# Q32M210 register map
File version: 1.0
Registers are 32-bit, read-write, no defined reset value unless marked. A register's access mark holds for its fields unless they carry their own. Offsets are from the block's base; [hi:lo] are bit positions; {n}, {i} and the like mark numbered series.

## DMA_Controller_Configuration_and_Control
Base 0x40000200
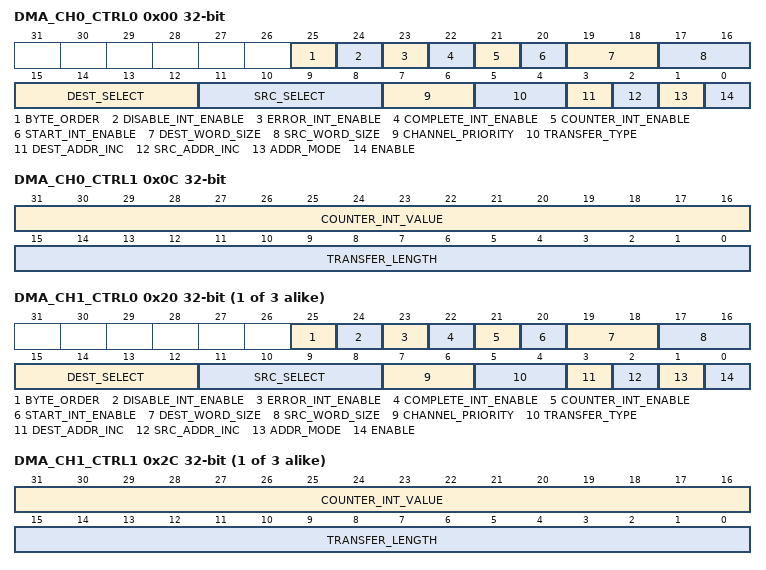
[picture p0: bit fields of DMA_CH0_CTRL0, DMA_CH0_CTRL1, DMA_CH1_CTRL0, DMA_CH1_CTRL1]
0x00 DMA_CH0_CTRL0 — DMA Channel 0 Control and Configuration
  [25] BYTE_ORDER — Select the byte ordering for the DMA channel
    0=DMA_CH0_LITTLE_ENDIAN (DMA channel 0 uses little endian mode); 1=DMA_CH0_BIG_ENDIAN (DMA channel 0 uses big endian mode)
  [24] DISABLE_INT_ENABLE — Raise an interrupt when the DMA channel is disabled
    0=DMA_CH0_DISABLE_INT_DISABLE (Disable channel disable indicating interrupts for DMA channel 0); 1=DMA_CH0_DISABLE_INT_ENABLE (Enable channel disable indicating interrupts for DMA channel 0)
  [23] ERROR_INT_ENABLE — Raise an interrupt when a state machine error occurs during a DMA transfer
    0=DMA_CH0_ERROR_INT_DISABLE (Disable error indicating interrupts for DMA channel 0); 1=DMA_CH0_ERROR_INT_ENABLE (Enable error indicating interrupts for DMA channel 0)
  [22] COMPLETE_INT_ENABLE — Raise an interrupt when the DMA transfer completes
    0=DMA_CH0_COMPLETE_INT_DISABLE (Disable completion interrupts for DMA channel 0); 1=DMA_CH0_COMPLETE_INT_ENABLE (Enable completion interrupts for DMA channel 0)
  [21] COUNTER_INT_ENABLE — Raise an interrupt when the DMA transfer reaches the counter value
    0=DMA_CH0_COUNTER_INT_DISABLE (Disable counter interrupts for DMA channel 0); 1=DMA_CH0_COUNTER_INT_ENABLE (Enable counter interrupts for DMA channel 0)
  [20] START_INT_ENABLE — Raise an interrupt when the DMA transfer starts
    0=DMA_CH0_START_INT_DISABLE (Disable start interrupts for DMA channel 0); 1=DMA_CH0_START_INT_ENABLE (Enable start interrupts for DMA channel 0)
  [19:18] DEST_WORD_SIZE — Select the destination word size
    0=DMA_CH0_DEST_WORD_SIZE_8 (Destination data uses 8-bit words); 1=DMA_CH0_DEST_WORD_SIZE_16 (Destination data uses 16-bit words); 2=DMA_CH0_DEST_WORD_SIZE_32 (Destination data uses 32-bit words)
  [17:16] SRC_WORD_SIZE — Select the source word size
    0=DMA_CH0_SRC_WORD_SIZE_8 (Source data uses 8-bit words); 1=DMA_CH0_SRC_WORD_SIZE_16 (Source data uses 16-bit words); 2=DMA_CH0_SRC_WORD_SIZE_32 (Source data uses 32-bit words)
  [15:12] DEST_SELECT — Select the request line for the destination
    1=DMA_CH0_DEST_DAC0 (Data writes are controlled by the DAC0 request line); 2=DMA_CH0_DEST_DAC1 (Data writes are controlled by the DAC1 request line); 3=DMA_CH0_DEST_USB (Data writes are controlled by the USB request line); 6=DMA_CH0_DEST_PCM (Data writes are controlled by the PCM request line); 7=DMA_CH0_DEST_SPI0 (Data writes are controlled by the SPI0 request line); 8=DMA_CH0_DEST_SPI1 (Data writes are controlled by the SPI1 request line); 9=DMA_CH0_DEST_I2C (Data writes are controlled by the I2C request line); 10=DMA_CH0_DEST_UART0 (Data writes are controlled by the UART0 request line); 11=DMA_CH0_DEST_UART1 (Data writes are controlled by the UART1 request line)
  [11:8] SRC_SELECT — Select the request line for the source
    0=DMA_CH0_SRC_ADC (Data reads are controlled by the ADC request line); 3=DMA_CH0_SRC_USB (Data reads are controlled by the USB request line); 6=DMA_CH0_SRC_PCM (Data reads are controlled by the PCM request line); 7=DMA_CH0_SRC_SPI0 (Data reads are controlled by the SPI0 request line); 8=DMA_CH0_SRC_SPI1 (Data reads are controlled by the SPI1 request line); 9=DMA_CH0_SRC_I2C (Data reads are controlled by the I2C request line); 10=DMA_CH0_SRC_UART0 (Data reads are controlled by the UART0 request line); 11=DMA_CH0_SRC_UART1 (Data reads are controlled by the UART1 request line)
  [7:6] CHANNEL_PRIORITY — Select the priority level for this channel
    0=DMA_CH0_PRIORITY_0 (Set the priority of DMA channel 0 to 0 (Highest)); 1=DMA_CH0_PRIORITY_1 (Set the priority of DMA channel 0 to 1); 2=DMA_CH0_PRIORITY_2 (Set the priority of DMA channel 0 to 2); 3=DMA_CH0_PRIORITY_3 (Set the priority of DMA channel 0 to 3 (Lowest))
  [5:4] TRANSFER_TYPE — Select the type of transfer implemented by DMA channel 0
    0=DMA_CH0_TRANSFER_M_TO_M (DMA channel 0 will provide a memory-to-memory data transfer); 1=DMA_CH0_TRANSFER_M_TO_P (DMA channel 0 will provide a memory-to-peripheral data transfer); 2=DMA_CH0_TRANSFER_P_TO_M (DMA channel 0 will provide a peripheral to memory data transfer)
  [3] DEST_ADDR_INC — Configure whether the destination address will be incremented
    0=DMA_CH0_DEST_ADDR_STATIC (Do not increment the destination address used by DMA channel 0); 1=DMA_CH0_DEST_ADDR_INC (Increment destination address used by DMA channel 0)
  [2] SRC_ADDR_INC — Configure whether the source address will be incremented
    0=DMA_CH0_SRC_ADDR_STATIC (Do not increment the source address used by DMA channel 0); 1=DMA_CH0_SRC_ADDR_INC (Increment source address used by DMA channel 0)
  [1] ADDR_MODE — Select the addressing mode for this channel
    0=DMA_CH0_ADDR_CIRC (Use circular addressing for DMA channel 0); 1=DMA_CH0_ADDR_LIN (Use linear addressing for DMA channel 0)
  [0] ENABLE — Enable DMA Channel 0
    0=DMA_CH0_DISABLE (Disable DMA channel 0); 1=DMA_CH0_ENABLE (Enable DMA channel 0)
0x04 DMA_CH0_SRC_BASE_ADDR — DMA Channel 0 Source Base Address
  [31:0] DMA_CH0_SRC_BASE_ADDR — Base address for the source of data transferred using DMA channel 0
0x08 DMA_CH0_DEST_BASE_ADDR — DMA Channel 0 Destination Base Address
  [31:0] DMA_CH0_DEST_BASE_ADDR — Base address for the destination of data transferred using DMA channel 0
0x0C DMA_CH0_CTRL1 — DMA Channel 0 Transfer Control
  [31:16] COUNTER_INT_VALUE — Raise an interrupt when the DMA transfer word count reaches this value
  [15:0] TRANSFER_LENGTH — The length, in words, of each data transfer using DMA channel 0
0x10 DMA_CH0_NEXT_SRC_ADDR — DMA Channel 0 Next Source Address
  [31:0] DMA_CH0_NEXT_SRC_ADDR — Address of the next data to be transferred using DMA channel 0
0x14 DMA_CH0_NEXT_DEST_ADDR — DMA Channel 0 Next Destination Address
  [31:0] DMA_CH0_NEXT_DEST_ADDR — Address where the next data to be transferred using DMA channel 0 will be stored
0x18 DMA_CH0_WORD_CNT — DMA Channel 0 Word Count
  [15:0] DMA_CH0_WORD_CNT — The number of words that have been transferred using DMA channel 0 during the current transfer
{0x0+0x20*i} DMA_CH{i}_CTRL0 (i=1..3) — DMA channel {i} Control and Configuration
  [25] BYTE_ORDER — Select the byte ordering for the DMA channel
    0=DMA_CH{i}_LITTLE_ENDIAN (DMA channel {i} uses little endian mode); 1=DMA_CH{i}_BIG_ENDIAN (DMA channel {i} uses big endian mode)
  [24] DISABLE_INT_ENABLE — Raise an interrupt when the DMA channel is disabled
    0=DMA_CH{i}_DISABLE_INT_DISABLE (Disable channel disable indicating interrupts for DMA channel {i}); 1=DMA_CH{i}_DISABLE_INT_ENABLE (Enable channel disable indicating interrupts for DMA channel {i})
  [23] ERROR_INT_ENABLE — Raise an interrupt when a state machine error occurs during a DMA transfer
    0=DMA_CH{i}_ERROR_INT_DISABLE (Disable error indicating interrupts for DMA channel {i}); 1=DMA_CH{i}_ERROR_INT_ENABLE (Enable error indicating interrupts for DMA channel {i})
  [22] COMPLETE_INT_ENABLE — Raise an interrupt when the DMA transfer completes
    0=DMA_CH{i}_COMPLETE_INT_DISABLE (Disable completion interrupts for DMA channel {i}); 1=DMA_CH{i}_COMPLETE_INT_ENABLE (Enable completion interrupts for DMA channel {i})
  [21] COUNTER_INT_ENABLE — Raise an interrupt when the DMA transfer reaches the counter value
    0=DMA_CH{i}_COUNTER_INT_DISABLE (Disable counter interrupts for DMA channel {i}); 1=DMA_CH{i}_COUNTER_INT_ENABLE (Enable counter interrupts for DMA channel {i})
  [20] START_INT_ENABLE — Raise an interrupt when the DMA transfer starts
    0=DMA_CH{i}_START_INT_DISABLE (Disable start interrupts for DMA channel {i}); 1=DMA_CH{i}_START_INT_ENABLE (Enable start interrupts for DMA channel {i})
  [19:18] DEST_WORD_SIZE — Select the destination word size
    0=DMA_CH{i}_DEST_WORD_SIZE_8 (Destination data uses 8-bit words); 1=DMA_CH{i}_DEST_WORD_SIZE_16 (Destination data uses 16-bit words); 2=DMA_CH{i}_DEST_WORD_SIZE_32 (Destination data uses 32-bit words)
  [17:16] SRC_WORD_SIZE — Select the source word size
    0=DMA_CH{i}_SRC_WORD_SIZE_8 (Source data uses 8-bit words); 1=DMA_CH{i}_SRC_WORD_SIZE_16 (Source data uses 16-bit words); 2=DMA_CH{i}_SRC_WORD_SIZE_32 (Source data uses 32-bit words)
  [15:12] DEST_SELECT — Select the request line for the destination
    1=DMA_CH{i}_DEST_DAC0 (Data writes are controlled by the DAC0 request line); 2=DMA_CH{i}_DEST_DAC1 (Data writes are controlled by the DAC1 request line); 3=DMA_CH{i}_DEST_USB (Data writes are controlled by the USB request line); 6=DMA_CH{i}_DEST_PCM (Data writes are controlled by the PCM request line); 7=DMA_CH{i}_DEST_SPI0 (Data writes are controlled by the SPI0 request line); 8=DMA_CH{i}_DEST_SPI1 (Data writes are controlled by the SPI1 request line); 9=DMA_CH{i}_DEST_I2C (Data writes are controlled by the I2C request line); 10=DMA_CH{i}_DEST_UART0 (Data writes are controlled by the UART0 request line); 11=DMA_CH{i}_DEST_UART1 (Data writes are controlled by the UART1 request line)
  [11:8] SRC_SELECT — Select the request line for the source
    0=DMA_CH{i}_SRC_ADC (Data reads are controlled by the ADC request line); 3=DMA_CH{i}_SRC_USB (Data reads are controlled by the USB request line); 6=DMA_CH{i}_SRC_PCM (Data reads are controlled by the PCM request line); 7=DMA_CH{i}_SRC_SPI0 (Data reads are controlled by the SPI0 request line); 8=DMA_CH{i}_SRC_SPI1 (Data reads are controlled by the SPI1 request line); 9=DMA_CH{i}_SRC_I2C (Data reads are controlled by the I2C request line); 10=DMA_CH{i}_SRC_UART0 (Data reads are controlled by the UART0 request line); 11=DMA_CH{i}_SRC_UART1 (Data reads are controlled by the UART1 request line)
  [7:6] CHANNEL_PRIORITY — Select the priority level for this channel
    0=DMA_CH{i}_PRIORITY_0 (Set the priority of DMA channel {i} to 0 (Highest)); 1=DMA_CH{i}_PRIORITY_1 (Set the priority of DMA channel {i} to 1); 2=DMA_CH{i}_PRIORITY_2 (Set the priority of DMA channel {i} to 2); 3=DMA_CH{i}_PRIORITY_3 (Set the priority of DMA channel {i} to 3 (Lowest))
  [5:4] TRANSFER_TYPE — Select the type of transfer implemented by DMA channel {i}
    0=DMA_CH{i}_TRANSFER_M_TO_M (DMA channel {i} will provide a memory-to-memory data transfer); 1=DMA_CH{i}_TRANSFER_M_TO_P (DMA channel {i} will provide a memory-to-peripheral data transfer); 2=DMA_CH{i}_TRANSFER_P_TO_M (DMA channel {i} will provide a peripheral to memory data transfer)
  [3] DEST_ADDR_INC — Configure whether the destination address will be incremented
    0=DMA_CH{i}_DEST_ADDR_STATIC (Do not increment the destination address used by DMA channel {i}); 1=DMA_CH{i}_DEST_ADDR_INC (Increment destination address used by DMA channel {i})
  [2] SRC_ADDR_INC — Configure whether the source address will be incremented
    0=DMA_CH{i}_SRC_ADDR_STATIC (Do not increment the source address used by DMA channel {i}); 1=DMA_CH{i}_SRC_ADDR_INC (Increment source address used by DMA channel {i})
  [1] ADDR_MODE — Select the addressing mode for this channel
    0=DMA_CH{i}_ADDR_CIRC (Use circular addressing for DMA channel {i}); 1=DMA_CH{i}_ADDR_LIN (Use linear addressing for DMA channel {i})
  [0] ENABLE — Enable DMA channel {i}
    0=DMA_CH{i}_DISABLE (Disable DMA channel {i}); 1=DMA_CH{i}_ENABLE (Enable DMA channel {i})
{0x4+0x20*i} DMA_CH{i}_SRC_BASE_ADDR (i=1..3) — DMA channel {i} Source Base Address
  [31:0] DMA_CH{i}_SRC_BASE_ADDR — Base address for the source of data transferred using DMA channel {i}
{0x8+0x20*i} DMA_CH{i}_DEST_BASE_ADDR (i=1..3) — DMA channel {i} Destination Base Address
  [31:0] DMA_CH{i}_DEST_BASE_ADDR — Base address for the destination of data transferred using DMA channel {i}
{0xC+0x20*i} DMA_CH{i}_CTRL1 (i=1..3) — DMA channel {i} Transfer Control
  [31:16] COUNTER_INT_VALUE — Raise an interrupt when the DMA transfer word count reaches this value
  [15:0] TRANSFER_LENGTH — The length, in words, of each data transfer using DMA channel {i}
{0x10+0x20*i} DMA_CH{i}_NEXT_SRC_ADDR (i=1..3) — DMA channel {i} Next Source Address
  [31:0] DMA_CH{i}_NEXT_SRC_ADDR — Address of the next data to be transferred using DMA channel {i}
{0x14+0x20*i} DMA_CH{i}_NEXT_DEST_ADDR (i=1..3) — DMA channel {i} Next Destination Address
  [31:0] DMA_CH{i}_NEXT_DEST_ADDR — Address where the next data to be transferred using DMA channel {i} will be stored
{0x18+0x20*i} DMA_CH{i}_WORD_CNT (i=1..3) — DMA channel {i} Word Count
  [15:0] DMA_CH{i}_WORD_CNT — The number of words that have been transferred using DMA channel {i} during the current transfer
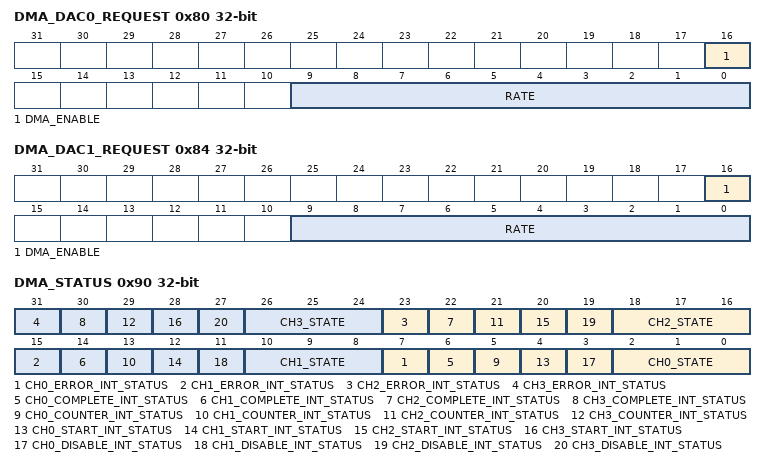
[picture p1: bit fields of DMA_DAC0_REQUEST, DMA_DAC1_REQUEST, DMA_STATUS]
0x80 DMA_DAC0_REQUEST — DMA Request Control for DAC0
  [16] DMA_ENABLE — Select whether DMA requests are enabled for the DAC0 request line
    0=DMA_DAC0_REQUEST_DISABLE (Disable the DAC0 DMA request line); 1=DMA_DAC0_REQUEST_ENABLE (Enable the DAC0 DMA request line)
  [9:0] RATE — Select how often a DAC0 DMA request will occur
0x84 DMA_DAC1_REQUEST — DMA Request Control for DAC1
  [16] DMA_ENABLE — Select whether DMA request are enabled for the DAC1 request line
    0=DMA_DAC1_REQUEST_DISABLE (Disable the DAC1 DMA request line); 1=DMA_DAC1_REQUEST_ENABLE (Enable the DAC1 DMA request line)
  [9:0] RATE — Select how often a DAC1 DMA request will occur
0x90 DMA_STATUS
  [8n+7] CH{n}_ERROR_INT_STATUS (n=0..3) — Indicate if a state machine error interrupt has occurred on DMA channel {n}
    1=DMA_CH{n}_ERROR_INT (Indicate that a state machine error interrupt has occurred)
  [8n+6] CH{n}_COMPLETE_INT_STATUS (n=0..3) — Indicate if a complete interrupt has occurred on DMA channel {n}
    1=DMA_CH{n}_COMPLETE_INT (Indicate that a complete interrupt has occurred)
  [8n+5] CH{n}_COUNTER_INT_STATUS (n=0..3) — Indicate if a counter interrupt has occurred on DMA channel {n}
    1=DMA_CH{n}_COUNTER_INT (Indicate that a counter interrupt has occurred)
  [8n+4] CH{n}_START_INT_STATUS (n=0..3) — Indicate if a start interrupt has occurred on DMA channel {n}
    1=DMA_CH{n}_START_INT (Indicate that a start interrupt has occurred)
  [8n+3] CH{n}_DISABLE_INT_STATUS (n=0..3) — Indicate if a channel disable interrupt has occurred on DMA channel {n}
    1=DMA_CH{n}_DISABLE_INT (Indicate that a channel disable interrupt has occurred)
  [8n+2:8n] CH{n}_STATE (n=0..3) — DMA channel {n} state
    0=DMA_CH{n}_IDLE (Indicate that DMA channel {n} is idle)
